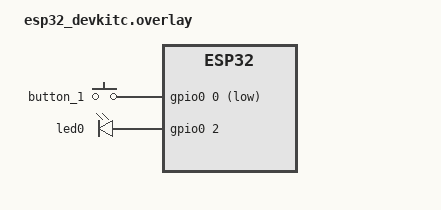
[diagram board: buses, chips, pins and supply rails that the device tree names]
/ {
    aliases {
        my-button = &button_1;
        my-led = &led0;
    };

    buttons {
        compatible = "gpio-keys";
        debounce-interval-ms = <50>;
        polling-mode;

        button_1: d0 {
            gpios = <&gpio0 0 (GPIO_ACTIVE_LOW | GPIO_PULL_UP)>;
        };
    };

    leds {
        compatible = "gpio-leds";
        led0: d13 {
            gpios = <&gpio0 2 GPIO_ACTIVE_HIGH>;
        };
    };
};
